# RA2A1 register map
Vendor: Renesas Electronics Corporation; Series: RA2; File version: 1.1
CPU: other r1p0, little endian, MPU, no FPU, VTOR, 2 interrupt priority bits
Registers are 8-bit, read-write, reset 0x0 unless marked. A register's access mark holds for its fields unless they carry their own. Offsets are from the block's base; [hi:lo] are bit positions; {n}, {i} and the like mark numbered series; 'fields as' and 'values as' point back to an identical list.

## IIC0 — Inter-Integrated Circuit 0
Base 0x40053000
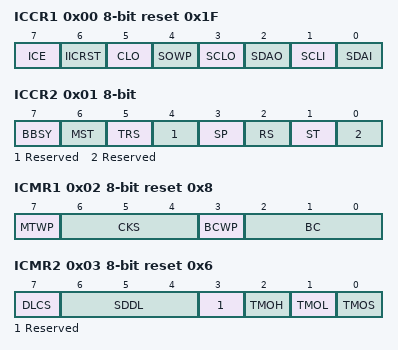
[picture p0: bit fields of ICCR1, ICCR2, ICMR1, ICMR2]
0x00 ICCR1 reset 0x1F — I2C Bus Control Register 1
  [7] ICE — I2C Bus Interface Enable
    0=Disable (SCLn and SDAn pins in inactive state); 1=Enable (SCLn and SDAn pins in active state)
  [6] IICRST — I2C Bus Interface Internal ResetNote:If an internal reset is initiated using the IICRST bit for a bus hang-up occurred during communication with the master device in slave mode, the states may become different between the slave device and the master device (due to the difference in the bit counter information).
    0=Releases the RIIC reset or internal reset; 1=Initiates the RIIC reset or internal reset
  [5] CLO — Extra SCL Clock Cycle Output
    0=Does not output an extra SCL clock cycle; 1=Outputs an extra SCL clock cycle
  [4] SOWP wo — SCLO/SDAO Write Protect
    0=Bits SCLO and SDAO can be written; 1=Bits SCLO and SDAO are protected
  [3] SCLO — SCL Output Control/Monitor
    0=(Read)The RIIC has driven the SCLn pin low. / (Write)The RIIC drives the SCLn pin low.; 1=(Read)The RIIC has released the SCLn pin. / (Write)The RIIC releases the SCLn pin.
  [2] SDAO — SDA Output Control/Monitor
    0=(Read)The RIIC has driven the SDAn pin low. / (Write)The RIIC drives the SDAn pin low.; 1=(Read)The RIIC has released the SDAn pin./ (Write)The RIIC releases the SDAn pin
  [1] SCLI ro — SCL Line Monitor
    0=SCLn line is low; 1=SCLn line is high
  [0] SDAI ro — SDA Line Monitor
    0=SDAn line is low; 1=SDAn line is high
0x01 ICCR2 — I2C Bus Control Register 2
  [7] BBSY ro — Bus Busy Detection Flag
    0=The I2C bus is released (bus free state); 1=The I2C bus is occupied (bus busy state)
  [6] MST — Master/Slave Mode
    0=Slave mode; 1=Master mode
  [5] TRS — Transmit/Receive Mode
    0=Receive mode; 1=Transmit mode
  [4] Reserved — This bit is read as 0. The write value should be 0.
  [3] SP — Stop Condition Issuance RequestNote: Writing to the SP bit is not possible while the setting of the BBSY flag is 0 (bus free state).Note: Do not set the SP bit to 1 while a restart condition is being issued.
    0=Does not request to issue a stop condition; 1=Requests to issue a stop condition
  [2] RS — Restart Condition Issuance RequestNote: Do not set the RS bit to 1 while issuing a stop condition.
    0=Does not request to issue a restart condition; 1=Requests to issue a restart condition
  [1] ST — Start Condition Issuance RequestSet the ST bit to 1 (start condition issuance request) when the BBSY flag is set to 0 (bus free state).
    0=Does not request to issue a start condition; 1=Requests to issue a start condition
  [0] Reserved — This bit is read as 0. The write value should be 0.
0x02 ICMR1 reset 0x8 — I2C Bus Mode Register 1
  [7] MTWP — MST/TRS Write Protect
    0=Disables writing to the MST and TRS bits in ICCR2; 1=Enables writing to the MST and TRS bits in ICCR2
  [6:4] CKS — Internal Reference Clock (fIIC) Selection ( fIIC = PCLKB / 2^CKS )
    0=PCLKB/1 clock; 1=PCLKB/2 clock; 2=PCLKB/4 clock; 3=PCLKB/8 clock; 4=PCLKB/16 clock; 5=PCLKB/32 clock; 6=PCLKB/64 clock; 7=PCLKB/128 clock
  [3] BCWP wo — BC Write Protect(This bit is read as 1.)
    0=Enables a value to be written in the BC[2:0] bits; 1=Disables a value to be written in the BC[2:0] bits
  [2:0] BC — Bit Counter
    0=9 bits; {v}={v+1} bits (v=1..7)
0x03 ICMR2 reset 0x6 — I2C Bus Mode Register 2
  [7] DLCS — SDA Output Delay Clock Source Selection
    0=The internal reference clock (fIIC) is selected as the clock source of the SDA output delay counter; 1=The internal reference clock divided by 2 (fIIC/2) is selected as the clock source of the SDA output delay counter
  [6:4] SDDL — SDA Output Delay Counter
    0=No output delay; 1=1 fIIC cycle (ICMR2.DLCS=0) / 1 or 2 fIIC cycles (ICMR2.DLCS=1); 2=2 fIIC cycles (ICMR2.DLCS=0) / 3 or 4 fIIC cycles (ICMR2.DLCS=1); 3=3 fIIC cycles (ICMR2.DLCS=0) / 5 or 6 fIIC cycles (ICMR2.DLCS=1); 4=4 fIIC cycles (ICMR2.DLCS=0) / 7 or 8 fIIC cycles (ICMR2.DLCS=1); 5=5 fIIC cycles (ICMR2.DLCS=0) / 9 or 10 fIIC cycles (ICMR2.DLCS=1); 6=6 fIIC cycles (ICMR2.DLCS=0) / 11 or 12 fIIC cycles (ICMR2.DLCS=1); 7=7 fIIC cycles (ICMR2.DLCS=0) / 13 or 14 fIIC cycles (ICMR2.DLCS=1)
  [3] Reserved — This bit is read as 0. The write value should be 0.
  [2] TMOH — Timeout H Count Control
    0=Count is disabled while the SCLn line is at a high level; 1=Count is enabled while the SCLn line is at a high level
  [1] TMOL — Timeout L Count Control
    0=Count is disabled while the SCLn line is at a low level; 1=Count is enabled while the SCLn line is at a low level
  [0] TMOS — Timeout Detection Time Selection
    0=Long mode is selected; 1=Short mode is selected
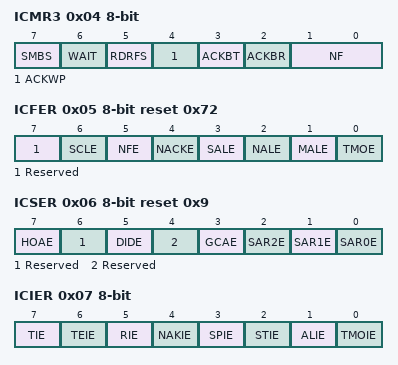
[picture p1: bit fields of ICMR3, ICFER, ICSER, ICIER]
0x04 ICMR3 — I2C Bus Mode Register 3
  [7] SMBS — SMBus/I2C Bus Selection
    0=The I2C bus is selected; 1=The SMBus is selected
  [6] WAIT — WAITNote: When the value of the WAIT bit is to be read, be sure to read the ICDRR beforehand.
    0=No WAIT (The period between ninth clock cycle and first clock cycle is not held low.); 1=WAIT (The period between ninth clock cycle and first clock cycle is held low.)
  [5] RDRFS — RDRF Flag Set Timing Selection
    0=The RDRF flag is set at the rising edge of the ninth SCL clock cycle. (The SCLn line is not held low at the falling edge of the eighth clock cycle.); 1=The RDRF flag is set at the rising edge of the eighth SCL clock cycle. (The SCLn line is held low at the falling edge of the eighth clock cycle.)
  [4] ACKWP — ACKBT Write Protect
    0=Modification of the ACKBT bit is disabled; 1=Modification of the ACKBT bit is enabled
  [3] ACKBT — Transmit Acknowledge
    0=A 0 is sent as the acknowledge bit (ACK transmission); 1=A 1 is sent as the acknowledge bit (NACK transmission)
  [2] ACKBR ro — Receive Acknowledge
    0=A 0 is received as the acknowledge bit (ACK reception); 1=A 1 is received as the acknowledge bit (NACK reception)
  [1:0] NF — Noise Filter Stage Selection
    0=Noise of up to one IIC cycle is filtered out (single-stage filter); 1=Noise of up to two IIC cycles is filtered out (2-stage filter); 2=Noise of up to three IIC cycles is filtered out (3-stage filter); 3=Noise of up to four IIC cycles is filtered out (4-stage filter)
0x05 ICFER reset 0x72 — I2C Bus Function Enable Register
  [7] Reserved — This bit is read as 0. The write value should be 0.
  [6] SCLE — SCL Synchronous Circuit Enable
    0=No SCL synchronous circuit is used; 1=An SCL synchronous circuit is used
  [5] NFE — Digital Noise Filter Circuit Enable
    0=No digital noise filter circuit is used; 1=A digital noise filter circuit is used
  [4] NACKE — NACK Reception Transfer Suspension Enable
    0=Transfer operation is not suspended during NACK reception (transfer suspension disabled); 1=Transfer operation is suspended during NACK reception (transfer suspension enabled)
  [3] SALE — Slave Arbitration-Lost Detection Enable
    0=Slave arbitration-lost detection is disabled; 1=Slave arbitration-lost detection is enabled
  [2] NALE — NACK Transmission Arbitration-Lost Detection Enable
    0=NACK transmission arbitration-lost detection is disabled; 1=NACK transmission arbitration-lost detection is enabled
  [1] MALE — Master Arbitration-Lost Detection Enable
    0=Master arbitration-lost detection is disabled; 1=Master arbitration-lost detection is enabled
  [0] TMOE — Timeout Function Enable
    0=The timeout function is disabled; 1=The timeout function is enabled
0x06 ICSER reset 0x9 — I2C Bus Status Enable Register
  [7] HOAE — Host Address Enable
    0=Host address detection is disabled; 1=Host address detection is enabled
  [6] Reserved — This bit is read as 0. The write value should be 0.
  [5] DIDE — Device-ID Address Detection Enable
    0=Device-ID address detection is disabled; 1=Device-ID address detection is enabled
  [4] Reserved — This bit is read as 0. The write value should be 0.
  [3] GCAE — General Call Address Enable
    0=General call address detection is disabled; 1=General call address detection is enabled
  [2] SAR2E — Slave Address Register 2 Enable
    0=Slave address in SARL2 and SARU2 is disabled; 1=Slave address in SARL2 and SARU2 is enabled
  [1] SAR1E — Slave Address Register 1 Enable
    0=Slave address in SARL1 and SARU1 is disabled; 1=Slave address in SARL1 and SARU1 is enabled
  [0] SAR0E — Slave Address Register 0 Enable
    0=Slave address in SARL0 and SARU0 is disabled; 1=Slave address in SARL0 and SARU0 is enabled
0x07 ICIER — I2C Bus Interrupt Enable Register
  [7] TIE — Transmit Data Empty Interrupt Request Enable
    0=Transmit data empty interrupt request (IICn_TXI) is disabled; 1=Transmit data empty interrupt request (IICn_TXI) is enabled
  [6] TEIE — Transmit End Interrupt Request Enable
    0=Transmit end interrupt request (IICn_TEI) is disabled; 1=Transmit end interrupt request (IICn_TEI) is enabled
  [5] RIE — Receive Data Full Interrupt Request Enable
    0=Receive data full interrupt request (IICn_RXI) is disabled; 1=Receive data full interrupt request (IICn_RXI) is enabled
  [4] NAKIE — NACK Reception Interrupt Request Enable
    0=NACK reception interrupt request (NAKI) is disabled; 1=NACK reception interrupt request (NAKI) is enabled
  [3] SPIE — Stop Condition Detection Interrupt Request Enable
    0=Stop condition detection interrupt request (SPI) is disabled; 1=Stop condition detection interrupt request (SPI) is enabled
  [2] STIE — Start Condition Detection Interrupt Request Enable
    0=Start condition detection interrupt request (STI) is disabled; 1=Start condition detection interrupt request (STI) is enabled
  [1] ALIE — Arbitration-Lost Interrupt Request Enable
    0=Arbitration-lost interrupt request (ALI) is disabled; 1=Arbitration-lost interrupt request (ALI) is enabled
  [0] TMOIE — Timeout Interrupt Request Enable
    0=Timeout interrupt request (TMOI) is disabled; 1=Timeout interrupt request (TMOI) is enabled
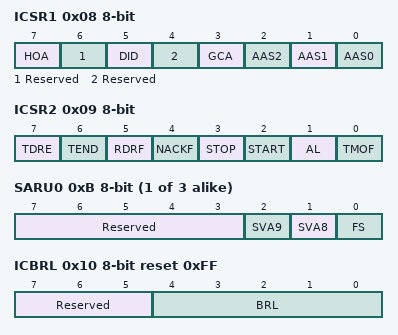
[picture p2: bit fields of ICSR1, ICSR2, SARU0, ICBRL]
0x08 ICSR1 — I2C Bus Status Register 1
  [7] HOA write-0-clears read-modifies — Host Address Detection Flag
    0=Host address is not detected; 1=Host address is detected
  [6] Reserved — This bit is read as 0. The write value should be 0.
  [5] DID write-0-clears read-modifies — Device-ID Address Detection Flag
    0=Device-ID command is not detected; 1=Device-ID command is detected
  [4] Reserved — This bit is read as 0. The write value should be 0.
  [3] GCA write-0-clears read-modifies — General Call Address Detection Flag
    0=General call address is not detected; 1=General call address is detected
  [2] AAS2 write-0-clears read-modifies — Slave Address 2 Detection Flag
    0=Slave address 2 is not detected; 1=Slave address 2 is detected
  [1] AAS1 write-0-clears read-modifies — Slave Address 1 Detection Flag
    0=Slave address 1 is not detected; 1=Slave address 1 is detected
  [0] AAS0 write-0-clears read-modifies — Slave Address 0 Detection Flag
    0=Slave address 0 is not detected; 1=Slave address 0 is detected
0x09 ICSR2 — I2C Bus Status Register 2
  [7] TDRE ro — Transmit Data Empty Flag
    0=ICDRT contains transmit data; 1=ICDRT contains no transmit data
  [6] TEND write-0-clears read-modifies — Transmit End Flag
    0=Data is being transmitted; 1=Data has been transmitted
  [5] RDRF write-0-clears read-modifies — Receive Data Full Flag
    0=ICDRR contains no receive data; 1=ICDRR contains receive data
  [4] NACKF write-0-clears read-modifies — NACK Detection Flag
    0=NACK is not detected; 1=NACK is detected
  [3] STOP write-0-clears read-modifies — Stop Condition Detection Flag
    0=Stop condition is not detected; 1=Stop condition is detected
  [2] START write-0-clears read-modifies — Start Condition Detection Flag
    0=Start condition is not detected; 1=Start condition is detected
  [1] AL write-0-clears read-modifies — Arbitration-Lost Flag
    0=Arbitration is not lost; 1=Arbitration is lost
  [0] TMOF write-0-clears read-modifies — Timeout Detection Flag
    0=Timeout is not detected; 1=Timeout is detected
{0xA+2i} SARL{i} (i=0..2) — Slave Address Register L{i}
  [7:0] SVA — A slave address is set.7-Bit Address = SVA[7:1] 10-Bit Address = { SVA9,SVA8,SVA[7:0] }
{0xB+2i} SARU{i} (i=0..2) — Slave Address Register U{i}
  [7:3] Reserved — These bits are read as 00000. The write value should be 00000.
  [2] SVA9 — 10-Bit Address(bit9)
  [1] SVA8 — 10-Bit Address(bit8)
  [0] FS — 7-Bit/10-Bit Address Format Selection
    0=The 7-bit address format is selected; 1=The 10-bit address format is selected
0x10 ICBRL reset 0xFF — I2C Bus Bit Rate Low-Level Register
  [7:5] Reserved — These bits are read as 111. The write value should be 111.
  [4:0] BRL — Bit Rate Low-Level Period(Low-level period of SCL clock)
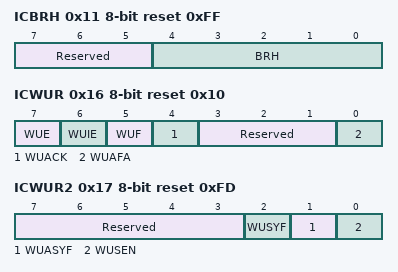
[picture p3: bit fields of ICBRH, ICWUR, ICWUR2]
0x11 ICBRH reset 0xFF — I2C Bus Bit Rate High-Level Register
  [7:5] Reserved — These bits are read as 111. The write value should be 111.
  [4:0] BRH — Bit Rate High-Level Period(High-level period of SCL clock)
0x12 ICDRT reset 0xFF — I2C Bus Transmit Data Register
  [7:0] ICDRT — 8-bit read-write register that stores transmit data.
0x13 ICDRR ro — I2C Bus Receive Data Register
  [7:0] ICDRR — 8-bit register that stores the received data
0x16 ICWUR reset 0x10 — I2C Bus Wake Up Unit Register
  [7] WUE — Wake Up function Enable
    0=Wake-up function is disabled; 1=Wake-up function is enabled
  [6] WUIE — Wake Up Interrupt Request Enable
    0=Wake Up Interrupt Request (WUI) is disabled; 1=Wake Up Interrupt Request (WUI) is enabled
  [5] WUF — Wake-Up Event Occurrence Flag
    0=Wake-Up event does not occur; 1=Wake-Up event occur
  [4] WUACK — Asynchronous/Synchronous Operation State Flag
    0=State of synchronous operation; 1=State of asynchronous operation
  [3:1] Reserved — These bits are read as 000. The write value should be 000.
  [0] WUAFA — Wake-Up Analog Filter Additional Selection
    0=Do not add the Wake Up analog filter; 1=Add the Wake Up analog filter
0x17 ICWUR2 reset 0xFD — Reserved
  [7:3] Reserved — These bits are read as 11111. The write value should be 11111.
  [2] WUSYF ro — Wake-Up function Synchronous operation status Flag
    0=RIIC asynchronous circuit enable condition; 1=RIIC synchronous circuit enable condition
  [1] WUASYF ro — Wake-Up function Asynchronous operation status Flag
    0=RIIC synchronous circuit enable condition; 1=RIIC asynchronous circuit enable condition
  [0] WUSEN — Wake-Up function Synchronous Enable
    0=RIIC asynchronous circuit enable; 1=RIIC synchronous circuit enable

## IIC1 — Inter-Integrated Circuit 1
Base 0x40053100
Registers as IIC0, without ICWUR, ICWUR2; these are added or differ:
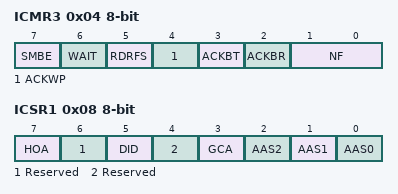
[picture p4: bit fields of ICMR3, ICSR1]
0x04 ICMR3 — I2C Bus Mode Register 3
  [7] SMBE — SMBus/I2C Bus Selection
    0=The I2C bus is selected; 1=The SMBus is selected
  [6] WAIT — WAITNote: When the value of the WAIT bit is to be read, be sure to read the ICDRR beforehand.
    0=No WAIT (The period between ninth clock cycle and first clock cycle is not held low.); 1=WAIT (The period between ninth clock cycle and first clock cycle is held low.)
  [5] RDRFS — RDRF Flag Set Timing Selection
    values as IIC0.ICMR3.RDRFS
  [4] ACKWP — ACKBT Write Protect
    0=Modification of the ACKBT bit is disabled; 1=Modification of the ACKBT bit is enabled
  [3] ACKBT — Transmit Acknowledge
    0=A 0 is sent as the acknowledge bit (ACK transmission); 1=A 1 is sent as the acknowledge bit (NACK transmission)
  [2] ACKBR ro — Receive Acknowledge
    0=A 0 is received as the acknowledge bit (ACK reception); 1=A 1 is received as the acknowledge bit (NACK reception)
  [1:0] NF — Noise Filter Stage Selection
    values as IIC0.ICMR3.NF
0x08 ICSR1 — I2C Bus Status Register 1
  [7] HOA write-0-clears read-modifies — Host Address Detection Flag
    0=Host address is not detected; 1=Host address is detected
  [6] Reserved — This bit is read as 0. The write value should be 0.
  [5] DID — Device-ID Address Detection Flag
    0=Device-ID command is not detected; 1=Device-ID command is detected
  [4] Reserved — This bit is read as 0. The write value should be 0.
  [3] GCA — General Call Address Detection Flag
    0=General call address is not detected; 1=General call address is detected
  [2] AAS2 write-0-clears read-modifies — Slave Address 2 Detection Flag
    0=Slave address 2 is not detected; 1=Slave address 2 is detected
  [1] AAS1 write-0-clears read-modifies — Slave Address 1 Detection Flag
    0=Slave address 1 is not detected; 1=Slave address 1 is detected
  [0] AAS0 write-0-clears read-modifies — Slave Address 0 Detection Flag
    0=Slave address 0 is not detected; 1=Slave address 0 is detected
